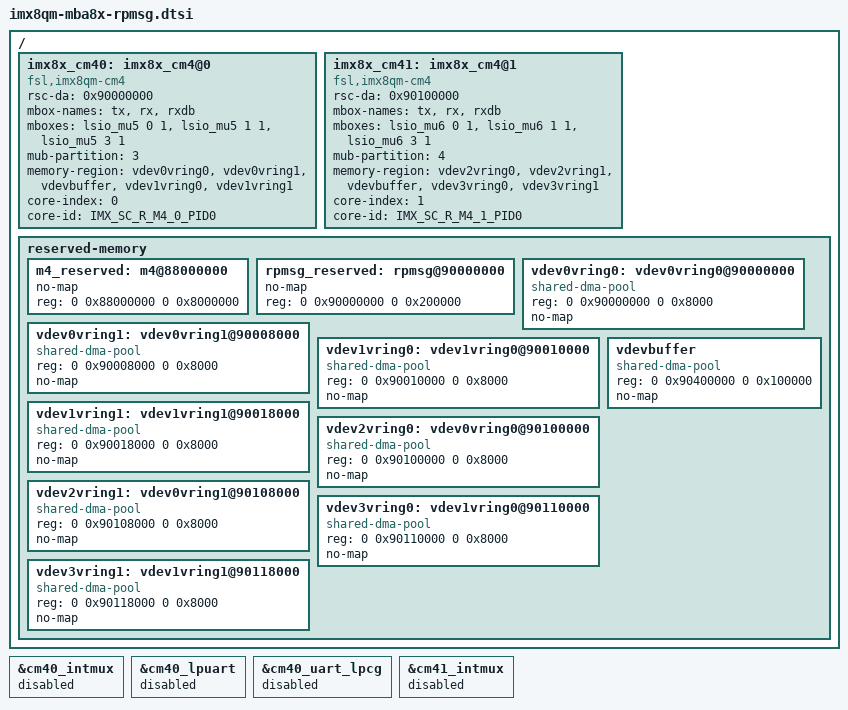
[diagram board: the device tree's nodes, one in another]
// SPDX-License-Identifier: (GPL-2.0-or-later OR MIT)
/*
 * Copyright 2021 TQ-Systems GmbH
 */

/ {
	imx8x_cm40: imx8x_cm4@0 {
		compatible = "fsl,imx8qm-cm4";
		rsc-da = <0x90000000>;
		mbox-names = "tx", "rx", "rxdb";
		mboxes = <&lsio_mu5 0 1
			  &lsio_mu5 1 1
			  &lsio_mu5 3 1>;
		/*
		 * partition ID the M4 is running in,
		 * assigned via imx-mkimage when building bootstream
		 */
		mub-partition = <3>;
		memory-region = <&vdev0vring0>, <&vdev0vring1>, <&vdevbuffer>,
				<&vdev1vring0>, <&vdev1vring1>;
		core-index = <0>;
		core-id = <IMX_SC_R_M4_0_PID0>;
		status = "okay";
	};

	imx8x_cm41: imx8x_cm4@1 {
		compatible = "fsl,imx8qm-cm4";
		rsc-da = <0x90100000>;
		mbox-names = "tx", "rx", "rxdb";
		mboxes = <&lsio_mu6 0 1
			  &lsio_mu6 1 1
			  &lsio_mu6 3 1>;
		/*
		 * partition ID the M4 is running in,
		 * assigned via imx-mkimage when building bootstream
		 */
		mub-partition = <4>;
		memory-region = <&vdev2vring0>, <&vdev2vring1>, <&vdevbuffer>,
				<&vdev3vring0>, <&vdev3vring1>;
		core-index = <1>;
		core-id = <IMX_SC_R_M4_1_PID0>;
		status = "okay";
	};

	reserved-memory {
		/*
		 * 0x8800_0000 ~ 0x8FFF_FFFF is reserved for M4
		 * Should not be used at A core and Linux side, when M4 running
		 * from RAM. Needs to be the same as reserved in
		 * board_system_config of SCU FW
		 */
		m4_reserved: m4@88000000 {
			no-map;
			reg = <0 0x88000000 0 0x8000000>;
		};

		rpmsg_reserved: rpmsg@90000000 {
			no-map;
			reg = <0 0x90000000 0 0x200000>;
		};

		vdev0vring0: vdev0vring0@90000000 {
			compatible = "shared-dma-pool";
			reg = <0 0x90000000 0 0x8000>;
			no-map;
		};

		vdev0vring1: vdev0vring1@90008000 {
			compatible = "shared-dma-pool";
			reg = <0 0x90008000 0 0x8000>;
			no-map;
		};

		vdev1vring0: vdev1vring0@90010000 {
			compatible = "shared-dma-pool";
			reg = <0 0x90010000 0 0x8000>;
			no-map;
		};

		vdev1vring1: vdev1vring1@90018000 {
			compatible = "shared-dma-pool";
			reg = <0 0x90018000 0 0x8000>;
			no-map;
		};

		vdev2vring0: vdev0vring0@90100000 {
			compatible = "shared-dma-pool";
			reg = <0 0x90100000 0 0x8000>;
			no-map;
		};

		vdev2vring1: vdev0vring1@90108000 {
			compatible = "shared-dma-pool";
			reg = <0 0x90108000 0 0x8000>;
			no-map;
		};

		vdev3vring0: vdev1vring0@90110000 {
			compatible = "shared-dma-pool";
			reg = <0 0x90110000 0 0x8000>;
			no-map;
		};

		vdev3vring1: vdev1vring1@90118000 {
			compatible = "shared-dma-pool";
			reg = <0 0x90118000 0 0x8000>;
			no-map;
		};

		vdevbuffer: vdevbuffer {
			compatible = "shared-dma-pool";
			reg = <0 0x90400000 0 0x100000>;
			no-map;
		};
	};
};

&cm40_intmux {
	status = "disabled";
};

&cm40_lpuart {
	status = "disabled";
};

&cm40_uart_lpcg {
	status = "disabled";
};

&cm41_intmux {
	status = "disabled";
};

/* imx8-ss-cm41.dtsi currently missing those nodes
&cm41_lpuart {
	status = "disabled";
};

&cm41_uart_lpcg {
	status = "disabled";
};
*/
